# tle984x register map
Vendor: Infineon; File version: 1.9.5
CPU: CM0 r2p1, little endian, no MPU, no FPU, 2 interrupt priority bits
Registers are 32-bit, read-write, reset 0x0 unless marked. A register's access mark holds for its fields unless they carry their own. Offsets are from the block's base; [hi:lo] are bit positions; 'fields as' and 'values as' point back to an identical list.

## MF — Measurement unit registers
Base 0x48018000
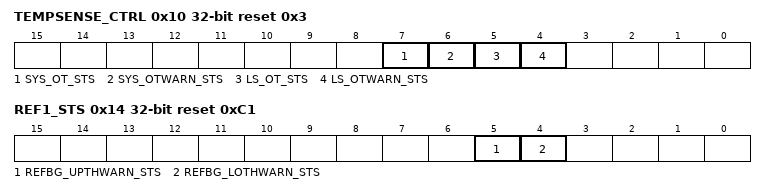
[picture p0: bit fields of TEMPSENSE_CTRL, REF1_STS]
0x10 TEMPSENSE_CTRL reset 0x3 — Temperature sensor control register
  [all] fields
    0=INACTIVE (Write clears status); 1=ACTIVE (Interrupt status set)
  [7] SYS_OT_STS ro — System overtemperature (MU) status
  [6] SYS_OTWARN_STS ro — System overtemperature warning (MU) status
  [5] LS_OT_STS ro — Low-side overtemperature (MU) status
  [4] LS_OTWARN_STS — Low-side overtemperature warning (MU) status
0x14 REF1_STS ro reset 0xC1 — Reference 1 status register
  [5] REFBG_UPTHWARN_STS — Status for overvoltage threshold measurement of internal VAREF
    0=UPPER_TRIG_RESET (Write clears status); 1=UPPER_TRIG_SET (Trigger status set)
  [4] REFBG_LOTHWARN_STS — Status for Undervoltage threshold measurement of internal VAREF
    values as REFBG_UPTHWARN_STS

## SSC1 — High-Speed Synchronous Serial Interface SSC1 registers
Base 0x48024000
Same registers: SSC2 0x48026000
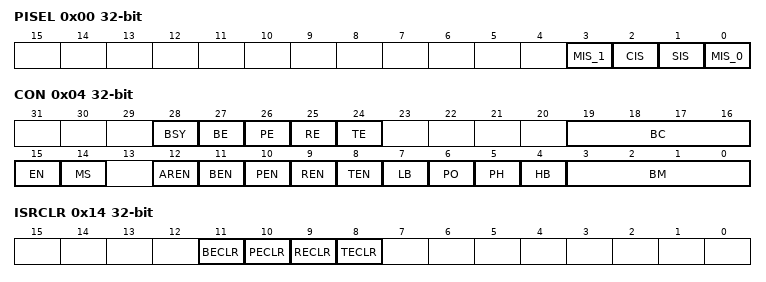
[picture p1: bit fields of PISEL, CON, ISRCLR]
0x00 PISEL — Port input select register
  [3] MIS_1 — Master mode input select bit 1 (master mode only)
    0=Default (Inputs selected according to MIS_0); 1=Do_not_use (Connects to unused pins)
  [2] CIS — Clock input select (slave mode only)
    0=SSCx_S_SCK ((x = 1 or 2, dependent form current SSC)); 1=SSC12_S_SCK (For both SSCs)
  [1] SIS — Slave mode input select (slave mode only)
    0=SSCx_S_MTSR ((x = 1 or 2, dependent form current SSC)); 1=SSC12_S_MTSR (For both SSCs)
  [0] MIS_0 — Master mode input select bit 0 (master mode only)
    0=SSCx_M_MRST ((x = 1 or 2, dependent form current SSC)); 1=SSC12_M_MRST (For both SSCs)
0x04 CON — Control register
  [28] BSY ro — Busy flag
  [27] BE ro — Baud rate error flag
    0=NO (Error); 1=ERROR (More than factor 2 or 0.5 between slave's actual and expected baud rate)
  [26] PE ro — Phase error flag
    0=NO (Error); 1=ERROR (Received data changes around sampling clock edge)
  [25] RE ro — Receive error flag
    0=NO (Error); 1=ERROR (Reception completed before the receive buffer was read)
  [24] TE ro — Transmit error flag
    0=NO (Error); 1=ERROR (Transfer starts with the slave's transmit buffer not being updated)
  [19:16] BC ro — Bit count field
  [15] EN — Enable bit
    0=Programming_mode (Transmission and reception disabled. Access to control bits); 1=Operating_mode (Transmission and reception enabled. Access to status flags and M/S control)
  [14] MS — Master select
    0=SLAVE (Slave mode. Operate on shift clock received through SCLK); 1=MASTER (Master mode. Generate shift clock and output it through SCLK)
  [12] AREN — Automatic reset enable
    0=N_A (No additional action upon a baud rate error); 1=RESET (The SSC is automatically reset upon a baud rate error)
  [11] BEN — Baud rate error enable
    0=IGNORE (Baud rate errors); 1=CHECK (Baud rate errors)
  [10] PEN — Phase error enable
    0=IGNORE (Phase errors); 1=CHECK (Phase errors)
  [9] REN — Receive error enable
    0=IGNORE (Receive errors); 1=CHECK (Receive errors)
  [8] TEN — Transmit error enable
    0=IGNORE (Transmit errors); 1=CHECK (Transmit errors)
  [7] LB — Loop back control
    0=NORMAL (Output); 1=LB (Receive input is connected with transmit output (half-duplex mode))
  [6] PO — Clock polarity control
    0=LOW (Idle clock line is low, leading clock edge is low-to-high transition); 1=HIGH (Idle clock line is high, leading clock edge is high-to-low transition)
  [5] PH — Clock phase control
    0=SHIFT (Transmit data on the leading clock edge, latch on trailing edge); 1=LATCH (Receive data on leading clock edge, shift on trailing edge)
  [4] HB — Heading control
    0=LSB (Transmit/Receive LSB first); 1=MSB (Transmit/Receive MSB first)
  [3:0] BM — Data width selection
    1=Const_1; 15=Transfer datawidth is 2 ... 16 bits (BM + 1)
0x08 TB — Transmitter buffer register
  [15:0] TB_VALUE — Transmit data register value
0x0C RB ro — Receiver buffer register
  [15:0] RB_VALUE — Receive data register value
0x10 BR — Baud-rate timer reload register
  [15:0] BR_VALUE — Baud rate timer/reload register value
0x14 ISRCLR — Interrupt status register clear
  [all] fields
    0=NO (No error clear); 1=CLEAR (Error clear)
  [11] BECLR wo — Baud rate error flag clear
  [10] PECLR wo — Phase error flag clear
  [9] RECLR wo — Receive error flag clear
  [8] TECLR wo — Transmit error flag clear
